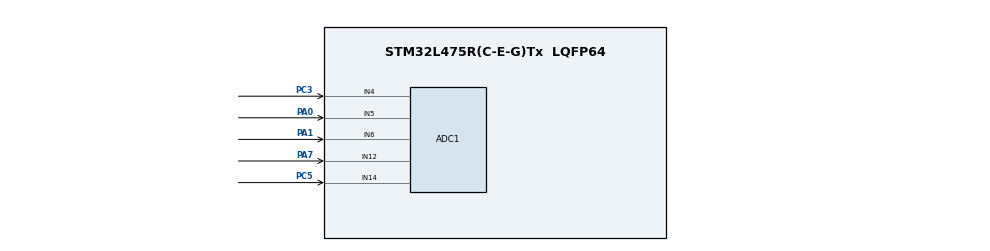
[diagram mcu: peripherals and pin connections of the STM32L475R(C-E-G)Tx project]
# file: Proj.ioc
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ADC1.Channel-7\#ChannelRegularConversion=ADC_CHANNEL_12
ADC1.ClockPrescaler=ADC_CLOCK_ASYNC_DIV4
ADC1.ContinuousConvMode=DISABLE
ADC1.EnableInjectedConversion=ENABLE
ADC1.EnableRegularConversion=ENABLE
ADC1.InjNumberOfConversion=4
ADC1.InjectedChannel-2\#ChannelInjectedConversion=ADC_CHANNEL_4
ADC1.InjectedChannel-3\#ChannelInjectedConversion=ADC_CHANNEL_5
ADC1.InjectedChannel-4\#ChannelInjectedConversion=ADC_CHANNEL_6
ADC1.InjectedChannel-5\#ChannelInjectedConversion=ADC_CHANNEL_14
ADC1.InjectedOffsetNumber-2\#ChannelInjectedConversion=ADC_OFFSET_NONE
ADC1.InjectedOffsetNumber-3\#ChannelInjectedConversion=ADC_OFFSET_NONE
ADC1.InjectedOffsetNumber-4\#ChannelInjectedConversion=ADC_OFFSET_NONE
ADC1.InjectedOffsetNumber-5\#ChannelInjectedConversion=ADC_OFFSET_NONE
ADC1.InjectedRank-2\#ChannelInjectedConversion=1
ADC1.InjectedRank-3\#ChannelInjectedConversion=2
ADC1.InjectedRank-4\#ChannelInjectedConversion=3
ADC1.InjectedRank-5\#ChannelInjectedConversion=4
ADC1.InjectedSamplingTime-2\#ChannelInjectedConversion=ADC_SAMPLETIME_2CYCLES_5
ADC1.InjectedSamplingTime-3\#ChannelInjectedConversion=ADC_SAMPLETIME_2CYCLES_5
ADC1.InjectedSamplingTime-4\#ChannelInjectedConversion=ADC_SAMPLETIME_2CYCLES_5
ADC1.InjectedSamplingTime-5\#ChannelInjectedConversion=ADC_SAMPLETIME_2CYCLES_5
ADC1.NbrOfConversionFlag=1
ADC1.OffsetNumber-7\#ChannelRegularConversion=ADC_OFFSET_NONE
ADC1.Rank-7\#ChannelRegularConversion=1
ADC1.Rank1_Channel=ADC_CHANNEL_4
ADC1.Rank2_Channel=ADC_CHANNEL_5
ADC1.Rank3_Channel=ADC_CHANNEL_6
ADC1.SamplingTime-7\#ChannelRegularConversion=ADC_SAMPLETIME_2CYCLES_5
ADC1.master=1
Mcu.Family=STM32L4
Mcu.Name=STM32L475R(C-E-G)Tx
Mcu.Package=LQFP64
NVIC.ADC1_2_IRQn=true\:0\:0\:false\:false\:true\:true\:true
NVIC.PriorityGroup=NVIC_PRIORITYGROUP_4
PA0.Signal=ADCx_IN5
PA1.Signal=ADCx_IN6
PA7.Signal=ADCx_IN12
PC3.Signal=ADCx_IN4
PC5.Signal=ADCx_IN14
ProjectManager.HeapSize=0x200
ProjectManager.StackSize=0x400
ProjectManager.TargetToolchain=TrueSTUDIO
RCC.ADCFreq_Value=32000000
RCC.HSE_VALUE=8000000
RCC.HSI_VALUE=16000000
RCC.LSE_VALUE=32768
RCC.MSI_VALUE=4000000
RCC.PLLSAI1N=16
RCC.USBFreq_Value=32000000
RCC.VCOOutputFreq_Value=32000000
SH.ADCx_IN12.0=ADC1_IN12,IN12-Single-Ended
SH.ADCx_IN14.0=ADC1_IN14,IN14-Single-Ended
SH.ADCx_IN4.0=ADC1_IN4,IN4-Single-Ended
SH.ADCx_IN5.0=ADC1_IN5,IN5-Single-Ended
SH.ADCx_IN6.0=ADC1_IN6,IN6-Single-Ended
board=custom

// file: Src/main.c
/* USER CODE BEGIN Header */
/**
  ******************************************************************************
  * @file           : main.c
  * @brief          : Main program body
  ******************************************************************************
  * @attention
  *
  * <h2><center>&copy; Copyright (c) 2020 STMicroelectronics.
  * All rights reserved.</center></h2>
  *
  * This software component is licensed by ST under BSD 3-Clause license,
  * the "License"; You may not use this file except in compliance with the
  * License. You may obtain a copy of the License at:
  *                        opensource.org/licenses/BSD-3-Clause
  *
  ******************************************************************************
  */
/* USER CODE END Header */

#include "main.h"

ADC_HandleTypeDef HADC1;

void SystemClock_Config(void);
static void MX_GPIO_Init(void);
static void MX_ADC1_Init(void);

int main(void)
{

  /* MCU Configuration--------------------------------------------------------*/

  /* Reset of all peripherals, Initializes the Flash interface and the Systick. */
  HAL_Init();

  /* Configure the system clock */
  SystemClock_Config();

  /* Initialize all configured peripherals */
  MX_GPIO_Init();
  MX_ADC1_Init();
  /* USER CODE BEGIN 2 */
//  HAL_ADCEx_InjectedStart_IT(&hadc1);
  HAL_ADC_Start_IT(&HADC1);//запустить прерывания АЦП
  /* USER CODE END 2 */

  /* Infinite loop */
  /* USER CODE BEGIN WHILE */
  while (1)
  {
	  asm("nop");
    /* USER CODE END WHILE */

  }
}

void SystemClock_Config(void)
{
  RCC_OscInitTypeDef RCC_OscInitStruct = {0};
  RCC_ClkInitTypeDef RCC_ClkInitStruct = {0};
  RCC_PeriphCLKInitTypeDef PeriphClkInit = {0};

  /** Initializes the CPU, AHB and APB busses clocks
  */
  RCC_OscInitStruct.OscillatorType = RCC_OSCILLATORTYPE_MSI;
  RCC_OscInitStruct.MSIState = RCC_MSI_ON;
  RCC_OscInitStruct.MSICalibrationValue = 0;
  RCC_OscInitStruct.MSIClockRange = RCC_MSIRANGE_6;
  RCC_OscInitStruct.PLL.PLLState = RCC_PLL_NONE;
  if (HAL_RCC_OscConfig(&RCC_OscInitStruct) != HAL_OK)
  {
    Error_Handler();
  }
  /** Initializes the CPU, AHB and APB busses clocks
  */
  RCC_ClkInitStruct.ClockType = RCC_CLOCKTYPE_HCLK|RCC_CLOCKTYPE_SYSCLK
                              |RCC_CLOCKTYPE_PCLK1|RCC_CLOCKTYPE_PCLK2;
  RCC_ClkInitStruct.SYSCLKSource = RCC_SYSCLKSOURCE_MSI;
  RCC_ClkInitStruct.AHBCLKDivider = RCC_SYSCLK_DIV1;
  RCC_ClkInitStruct.APB1CLKDivider = RCC_HCLK_DIV1;
  RCC_ClkInitStruct.APB2CLKDivider = RCC_HCLK_DIV1;

  if (HAL_RCC_ClockConfig(&RCC_ClkInitStruct, FLASH_LATENCY_0) != HAL_OK)
  {
    Error_Handler();
  }
  PeriphClkInit.PeriphClockSelection = RCC_PERIPHCLK_ADC;
  PeriphClkInit.AdcClockSelection = RCC_ADCCLKSOURCE_PLLSAI1;
  PeriphClkInit.PLLSAI1.PLLSAI1Source = RCC_PLLSOURCE_MSI;
  PeriphClkInit.PLLSAI1.PLLSAI1M = 1;
  PeriphClkInit.PLLSAI1.PLLSAI1N = 16;
  PeriphClkInit.PLLSAI1.PLLSAI1P = RCC_PLLP_DIV7;
  PeriphClkInit.PLLSAI1.PLLSAI1Q = RCC_PLLQ_DIV2;
  PeriphClkInit.PLLSAI1.PLLSAI1R = RCC_PLLR_DIV2;
  PeriphClkInit.PLLSAI1.PLLSAI1ClockOut = RCC_PLLSAI1_ADC1CLK;
  if (HAL_RCCEx_PeriphCLKConfig(&PeriphClkInit) != HAL_OK)
  {
    Error_Handler();
  }
  /** Configure the main internal regulator output voltage
  */
  if (HAL_PWREx_ControlVoltageScaling(PWR_REGULATOR_VOLTAGE_SCALE1) != HAL_OK)
  {
    Error_Handler();
  }
}

static void MX_ADC1_Init(void)
{

  ADC_MultiModeTypeDef multimode = {0};
  ADC_InjectionConfTypeDef sConfigInjected = {0};
  ADC_ChannelConfTypeDef sConfig = {0};

  /** Common config
  */
  HADC1.Instance = ADC1;
  HADC1.Init.ClockPrescaler = ADC_CLOCK_ASYNC_DIV4;
  HADC1.Init.Resolution = ADC_RESOLUTION_12B;
  HADC1.Init.DataAlign = ADC_DATAALIGN_RIGHT;
  HADC1.Init.ScanConvMode = ADC_SCAN_ENABLE;
  HADC1.Init.EOCSelection = ADC_EOC_SINGLE_CONV;
  HADC1.Init.LowPowerAutoWait = DISABLE;
  HADC1.Init.ContinuousConvMode = ENABLE;
  HADC1.Init.NbrOfConversion = 1;
  HADC1.Init.DiscontinuousConvMode = DISABLE;
  HADC1.Init.ExternalTrigConv = ADC_SOFTWARE_START;
  HADC1.Init.ExternalTrigConvEdge = ADC_EXTERNALTRIGCONVEDGE_NONE;
  HADC1.Init.DMAContinuousRequests = DISABLE;
  HADC1.Init.Overrun = ADC_OVR_DATA_PRESERVED;
  HADC1.Init.OversamplingMode = DISABLE;
  if (HAL_ADC_Init(&HADC1) != HAL_OK)
  {
    Error_Handler();
  }
  /** Configure the ADC multi-mode
  */
  multimode.Mode = ADC_MODE_INDEPENDENT;
  if (HAL_ADCEx_MultiModeConfigChannel(&HADC1, &multimode) != HAL_OK)
  {
    Error_Handler();
  }
  /** Configure Injected Channel
  */
  sConfigInjected.InjectedChannel = ADC_CHANNEL_4;
  sConfigInjected.InjectedRank = ADC_INJECTED_RANK_1;
  sConfigInjected.InjectedSamplingTime = ADC_SAMPLETIME_2CYCLES_5;
  sConfigInjected.InjectedSingleDiff = ADC_SINGLE_ENDED;
  sConfigInjected.InjectedOffsetNumber = ADC_OFFSET_NONE;
  sConfigInjected.InjectedOffset = 0;
  sConfigInjected.InjectedNbrOfConversion = 4;
  sConfigInjected.InjectedDiscontinuousConvMode = DISABLE;
  sConfigInjected.AutoInjectedConv = DISABLE;
  sConfigInjected.QueueInjectedContext = DISABLE;
  sConfigInjected.ExternalTrigInjecConv = ADC_INJECTED_SOFTWARE_START;
  sConfigInjected.ExternalTrigInjecConvEdge = ADC_EXTERNALTRIGINJECCONV_EDGE_NONE;
  sConfigInjected.InjecOversamplingMode = DISABLE;
  if (HAL_ADCEx_InjectedConfigChannel(&HADC1, &sConfigInjected) != HAL_OK)
  {
    Error_Handler();
  }
  /** Configure Injected Channel
  */
  sConfigInjected.InjectedChannel = ADC_CHANNEL_5;
  sConfigInjected.InjectedRank = ADC_INJECTED_RANK_2;
  if (HAL_ADCEx_InjectedConfigChannel(&HADC1, &sConfigInjected) != HAL_OK)
  {
    Error_Handler();
  }
  /** Configure Injected Channel
  */
  sConfigInjected.InjectedChannel = ADC_CHANNEL_6;
  sConfigInjected.InjectedRank = ADC_INJECTED_RANK_3;
  if (HAL_ADCEx_InjectedConfigChannel(&HADC1, &sConfigInjected) != HAL_OK)
  {
    Error_Handler();
  }
  /** Configure Injected Channel
  */
  sConfigInjected.InjectedChannel = ADC_CHANNEL_14;
  sConfigInjected.InjectedRank = ADC_INJECTED_RANK_4;
  if (HAL_ADCEx_InjectedConfigChannel(&HADC1, &sConfigInjected) != HAL_OK)
  {
    Error_Handler();
  }
  /** Configure Regular Channel
  */
  sConfig.Channel = ADC_CHANNEL_12;
  sConfig.Rank = ADC_REGULAR_RANK_1;
  sConfig.SamplingTime = ADC_SAMPLETIME_2CYCLES_5;
  sConfig.SingleDiff = ADC_SINGLE_ENDED;
  sConfig.OffsetNumber = ADC_OFFSET_NONE;
  sConfig.Offset = 0;
  if (HAL_ADC_ConfigChannel(&HADC1, &sConfig) != HAL_OK)
  {
    Error_Handler();
  }

}

static void MX_GPIO_Init(void)
{

  /* GPIO Ports Clock Enable */
  __HAL_RCC_GPIOC_CLK_ENABLE();
  __HAL_RCC_GPIOA_CLK_ENABLE();

}

/* USER CODE BEGIN 4 */
void __attribute__((optimize("O0"))) HAL_ADCEx_InjectedConvCpltCallback(ADC_HandleTypeDef* hadc1)
{
	//внешний источник
	uint16_t extBacup = HAL_ADCEx_InjectedGetValue(hadc1, ADC_INJECTED_RANK_1);
	//220V
	uint16_t ch220 = HAL_ADCEx_InjectedGetValue(hadc1, ADC_INJECTED_RANK_2);
	//аккум
	uint16_t accumIn = HAL_ADCEx_InjectedGetValue(hadc1, ADC_INJECTED_RANK_3);
	//внешний
	uint16_t extAccum = HAL_ADCEx_InjectedGetValue(hadc1, ADC_INJECTED_RANK_4);
	asm("nop");
	 HAL_ADCEx_InjectedStart_IT(hadc1);
}

void __attribute__((optimize("O0"))) HAL_ADC_ConvCpltCallback(ADC_HandleTypeDef* hadc)
{

	uint16_t accumCharge = HAL_ADC_GetValue(hadc);//взяли результат
	//HAL_ADC_Start_IT(&HADC1);//при вызове прерывания преобразование будет остановлено. запустить прерывания АЦП снова.
	asm("nop");
}

/* USER CODE END 4 */

void Error_Handler(void)
{
}

/************************ (C) COPYRIGHT STMicroelectronics *****END OF FILE****/
